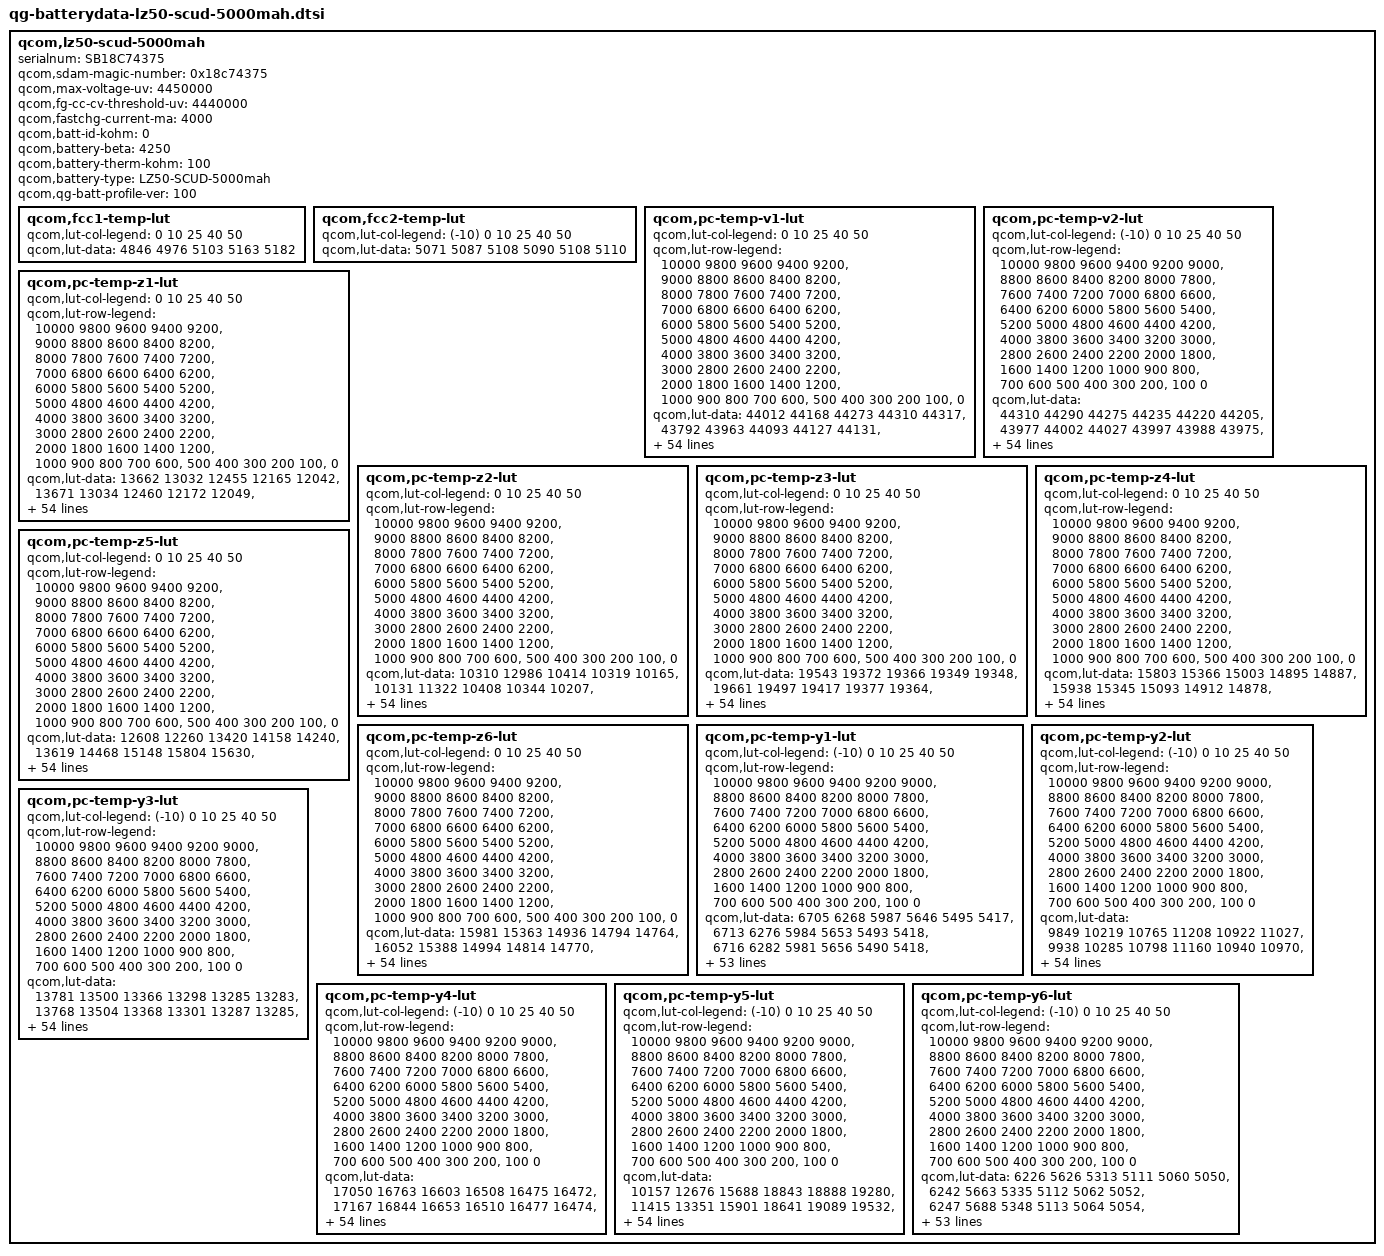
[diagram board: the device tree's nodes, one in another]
qcom,lz50-scud-5000mah {
    /* 4703262_Lenovo_Nairobi_SCUD_5000mAH_PM7250B_averaged_MasterSlave_Jul27th2020 */
    serialnum = "SB18C74375";
    qcom,sdam-magic-number = <0x18c74375>;
    qcom,max-voltage-uv = <4450000>;
    qcom,fg-cc-cv-threshold-uv = <4440000>;
    qcom,fastchg-current-ma = <4000>;
    qcom,batt-id-kohm = <0>;
    qcom,battery-beta = <4250>;
    qcom,battery-therm-kohm = <100>;
    qcom,battery-type = "LZ50-SCUD-5000mah";
    qcom,qg-batt-profile-ver = <100>;

	qcom,fcc1-temp-lut {
		qcom,lut-col-legend = <0 10 25 40 50>;
		qcom,lut-data = <4846 4976 5103 5163 5182>;
	};

	qcom,fcc2-temp-lut {
		qcom,lut-col-legend = <(-10) 0 10 25 40 50>;
		qcom,lut-data = <5071 5087 5108 5090 5108 5110>;
	};

	qcom,pc-temp-v1-lut {
		qcom,lut-col-legend = <0 10 25 40 50>;
		qcom,lut-row-legend = <10000 9800 9600 9400 9200>,
			<9000 8800 8600 8400 8200>,
			<8000 7800 7600 7400 7200>,
			<7000 6800 6600 6400 6200>,
			<6000 5800 5600 5400 5200>,
			<5000 4800 4600 4400 4200>,
			<4000 3800 3600 3400 3200>,
			<3000 2800 2600 2400 2200>,
			<2000 1800 1600 1400 1200>,
			<1000 900 800 700 600>,
			<500 400 300 200 100>,
			<0>;
		qcom,lut-data = <44012 44168 44273 44310 44317>,
			<43792 43963 44093 44127 44131>,
			<43564 43752 43903 43945 43953>,
			<43332 43534 43704 43752 43763>,
			<43096 43309 43491 43549 43562>,
			<42854 43076 43263 43331 43347>,
			<42611 42835 43029 43100 43119>,
			<42371 42590 42786 42863 42884>,
			<42132 42346 42538 42618 42641>,
			<41897 42103 42293 42372 42394>,
			<41666 41865 42051 42127 42148>,
			<41440 41631 41810 41883 41904>,
			<41221 41404 41572 41644 41664>,
			<41009 41183 41338 41407 41428>,
			<40797 40968 41113 41177 41199>,
			<40585 40759 40894 40953 40976>,
			<40378 40551 40684 40736 40759>,
			<40188 40350 40480 40531 40551>,
			<40011 40163 40284 40335 40351>,
			<39843 39987 40103 40145 40159>,
			<39681 39811 39929 39971 39983>,
			<39525 39636 39704 39772 39790>,
			<39373 39454 39378 39478 39515>,
			<39226 39232 39102 39176 39217>,
			<39084 38969 38957 39009 39039>,
			<38944 38775 38851 38903 38928>,
			<38805 38665 38753 38803 38825>,
			<38683 38582 38664 38702 38717>,
			<38572 38512 38581 38605 38613>,
			<38477 38452 38502 38510 38511>,
			<38412 38398 38428 38420 38412>,
			<38362 38346 38361 38337 38322>,
			<38318 38297 38300 38262 38245>,
			<38279 38254 38240 38192 38171>,
			<38243 38216 38184 38124 38098>,
			<38205 38176 38128 38059 38026>,
			<38169 38136 38076 37998 37957>,
			<38126 38092 38027 37944 37891>,
			<38062 38027 37961 37876 37814>,
			<37978 37930 37864 37776 37710>,
			<37875 37817 37748 37655 37588>,
			<37738 37686 37623 37530 37460>,
			<37587 37538 37483 37393 37321>,
			<37418 37369 37319 37235 37165>,
			<37307 37229 37175 37100 37033>,
			<37209 37142 37092 37018 36959>,
			<37174 37113 37065 36994 36933>,
			<37146 37087 37049 36976 36912>,
			<37109 37072 37025 36951 36885>,
			<37031 37000 36943 36856 36777>,
			<36747 36694 36649 36531 36438>,
			<36262 36227 36184 36059 35964>,
			<35638 35618 35576 35447 35357>,
			<34773 34769 34745 34607 34518>,
			<33356 33410 33443 33282 33195>,
			<30000 30000 30000 30000 30000>;
	};

	qcom,pc-temp-v2-lut {
		qcom,lut-col-legend = <(-10) 0 10 25 40 50>;
		qcom,lut-row-legend = <10000 9800 9600 9400 9200 9000>,
			<8800 8600 8400 8200 8000 7800>,
			<7600 7400 7200 7000 6800 6600>,
			<6400 6200 6000 5800 5600 5400>,
			<5200 5000 4800 4600 4400 4200>,
			<4000 3800 3600 3400 3200 3000>,
			<2800 2600 2400 2200 2000 1800>,
			<1600 1400 1200 1000 900 800>,
			<700 600 500 400 300 200>,
			<100 0>;
		qcom,lut-data = <44310 44290 44275 44235 44220 44205>,
			<43977 44002 44027 43997 43988 43975>,
			<43674 43735 43788 43765 43760 43749>,
			<43405 43491 43561 43541 43540 43530>,
			<43169 43272 43347 43325 43328 43319>,
			<42934 43045 43123 43103 43107 43100>,
			<42681 42799 42880 42864 42871 42865>,
			<42431 42545 42630 42619 42628 42624>,
			<42205 42289 42380 42375 42385 42382>,
			<41999 42029 42129 42128 42138 42136>,
			<41765 41783 41883 41885 41894 41893>,
			<41442 41557 41641 41645 41653 41652>,
			<41132 41340 41405 41408 41416 41415>,
			<40965 41132 41172 41177 41183 41182>,
			<40860 40931 40945 40951 40956 40955>,
			<40693 40708 40733 40733 40737 40735>,
			<40297 40446 40544 40522 40526 40522>,
			<39868 40177 40347 40319 40322 40316>,
			<39621 39922 40107 40132 40134 40128>,
			<39437 39674 39841 39953 39950 39946>,
			<39253 39443 39591 39738 39735 39736>,
			<39063 39226 39348 39459 39474 39483>,
			<38876 39027 39132 39196 39229 39243>,
			<38674 38852 38947 38998 39027 39039>,
			<38473 38691 38785 38829 38849 38857>,
			<38337 38518 38639 38684 38702 38709>,
			<38246 38322 38510 38560 38578 38584>,
			<38173 38172 38390 38449 38467 38471>,
			<38106 38090 38278 38343 38363 38364>,
			<38046 38028 38172 38244 38268 38266>,
			<37987 37974 38068 38155 38184 38179>,
			<37926 37926 37967 38074 38108 38100>,
			<37866 37878 37889 37998 38032 38022>,
			<37803 37828 37834 37930 37955 37942>,
			<37740 37777 37789 37865 37873 37858>,
			<37671 37722 37744 37792 37781 37758>,
			<37598 37663 37703 37713 37682 37647>,
			<37520 37597 37653 37632 37584 37542>,
			<37435 37522 37590 37553 37490 37447>,
			<37347 37437 37513 37470 37396 37353>,
			<37261 37336 37412 37378 37305 37261>,
			<37175 37220 37284 37274 37209 37161>,
			<37094 37092 37130 37142 37073 37014>,
			<37016 36961 36982 37005 36947 36889>,
			<36935 36844 36862 36900 36856 36806>,
			<36840 36755 36781 36857 36825 36774>,
			<36789 36717 36742 36841 36812 36760>,
			<36729 36681 36694 36820 36792 36741>,
			<36654 36623 36630 36780 36748 36694>,
			<36541 36515 36507 36658 36584 36509>,
			<36313 36269 36216 36306 36173 36089>,
			<35910 35799 35706 35777 35623 35539>,
			<35268 35125 35011 35088 34896 34809>,
			<34320 34126 34049 34132 33865 33785>,
			<32928 32522 32490 32681 32348 32275>,
			<29705 26763 27162 27333 26870 27058>;
	};

	qcom,pc-temp-z1-lut {
		qcom,lut-col-legend = <0 10 25 40 50>;
		qcom,lut-row-legend = <10000 9800 9600 9400 9200>,
			<9000 8800 8600 8400 8200>,
			<8000 7800 7600 7400 7200>,
			<7000 6800 6600 6400 6200>,
			<6000 5800 5600 5400 5200>,
			<5000 4800 4600 4400 4200>,
			<4000 3800 3600 3400 3200>,
			<3000 2800 2600 2400 2200>,
			<2000 1800 1600 1400 1200>,
			<1000 900 800 700 600>,
			<500 400 300 200 100>,
			<0>;
		qcom,lut-data = <13662 13032 12455 12165 12042>,
			<13671 13034 12460 12172 12049>,
			<13681 13034 12453 12162 12039>,
			<13688 13031 12451 12155 12033>,
			<13691 13027 12449 12149 12029>,
			<13695 13025 12447 12142 12024>,
			<13698 13030 12444 12136 12019>,
			<13686 13034 12434 12130 12016>,
			<13659 13030 12420 12125 12012>,
			<13648 13017 12414 12120 12011>,
			<13660 13002 12411 12116 12011>,
			<13673 12988 12407 12113 12012>,
			<13671 12974 12402 12113 12013>,
			<13651 12970 12399 12114 12015>,
			<13627 12970 12399 12115 12016>,
			<13600 12969 12399 12115 12016>,
			<13575 12965 12399 12114 12016>,
			<13571 12961 12398 12115 12016>,
			<13580 12962 12398 12116 12018>,
			<13586 12967 12400 12116 12019>,
			<13574 12969 12404 12117 12020>,
			<13553 12968 12405 12118 12021>,
			<13540 12967 12405 12118 12021>,
			<13522 12968 12405 12118 12022>,
			<13507 12968 12407 12118 12022>,
			<13512 12969 12411 12121 12025>,
			<13528 12974 12416 12124 12027>,
			<13537 12982 12421 12127 12029>,
			<13539 12986 12425 12132 12031>,
			<13540 12991 12427 12136 12035>,
			<13546 12996 12429 12140 12040>,
			<13563 13002 12433 12144 12046>,
			<13578 13008 12440 12149 12050>,
			<13589 13010 12447 12155 12055>,
			<13598 13010 12455 12161 12061>,
			<13602 13011 12462 12167 12067>,
			<13598 13018 12468 12173 12072>,
			<13595 13028 12474 12178 12076>,
			<13604 13039 12479 12183 12080>,
			<13618 13054 12483 12187 12085>,
			<13625 13064 12487 12192 12089>,
			<13622 13068 12493 12196 12092>,
			<13627 13072 12500 12202 12096>,
			<13673 13081 12509 12207 12099>,
			<13683 13097 12517 12214 12104>,
			<13654 13085 12521 12221 12109>,
			<13651 13110 12519 12220 12108>,
			<13646 13109 12523 12221 12109>,
			<13641 13108 12528 12223 12113>,
			<13675 13103 12534 12231 12119>,
			<13672 13115 12538 12239 12125>,
			<13724 13118 12548 12247 12132>,
			<13685 13157 12558 12259 12145>,
			<13743 13188 12584 12275 12163>,
			<13743 13188 12584 12275 12163>,
			<13743 13188 12584 12275 12163>;
	};

	qcom,pc-temp-z2-lut {
		qcom,lut-col-legend = <0 10 25 40 50>;
		qcom,lut-row-legend = <10000 9800 9600 9400 9200>,
			<9000 8800 8600 8400 8200>,
			<8000 7800 7600 7400 7200>,
			<7000 6800 6600 6400 6200>,
			<6000 5800 5600 5400 5200>,
			<5000 4800 4600 4400 4200>,
			<4000 3800 3600 3400 3200>,
			<3000 2800 2600 2400 2200>,
			<2000 1800 1600 1400 1200>,
			<1000 900 800 700 600>,
			<500 400 300 200 100>,
			<0>;
		qcom,lut-data = <10310 12986 10414 10319 10165>,
			<10131 11322 10408 10344 10207>,
			<10161 10409 10417 10342 10247>,
			<10202 10368 10426 10387 10310>,
			<10209 10340 10423 10414 10356>,
			<10208 10307 10395 10381 10350>,
			<10207 10273 10361 10322 10328>,
			<10204 10241 10327 10290 10305>,
			<10197 10217 10297 10271 10275>,
			<10188 10198 10360 10253 10254>,
			<10171 10182 10578 10228 10242>,
			<10153 10169 10652 10208 10229>,
			<10137 10160 10443 10207 10225>,
			<10122 10160 10238 10210 10219>,
			<10107 10163 10235 10216 10216>,
			<10092 10168 10258 10237 10216>,
			<10080 10178 10276 10257 10216>,
			<10083 10194 10288 10265 10229>,
			<10150 10210 10299 10269 10255>,
			<10210 10229 10310 10270 10268>,
			<10186 10247 10323 10273 10264>,
			<10120 10264 10346 10284 10264>,
			<10097 10281 10405 10357 10314>,
			<10107 10300 10447 10451 10393>,
			<10121 10320 10411 10413 10381>,
			<10134 10329 10346 10228 10238>,
			<10147 10324 10331 10144 10159>,
			<10159 10317 10337 10162 10174>,
			<10169 10312 10346 10195 10209>,
			<10178 10306 10360 10257 10302>,
			<10184 10303 10375 10353 10482>,
			<10189 10305 10380 10395 10539>,
			<10194 10310 10382 10412 10457>,
			<10201 10316 10384 10417 10357>,
			<10210 10325 10393 10390 10291>,
			<10219 10333 10403 10346 10239>,
			<10231 10339 10409 10340 10237>,
			<10244 10346 10418 10357 10286>,
			<10256 10357 10432 10380 10337>,
			<10269 10374 10461 10431 10373>,
			<10282 10388 10484 10483 10406>,
			<10297 10395 10486 10495 10436>,
			<10319 10403 10486 10500 10465>,
			<10364 10417 10485 10496 10479>,
			<10124 10527 10504 10449 10456>,
			<10244 10593 10527 10328 10293>,
			<9989 10605 10521 10325 10276>,
			<9808 10599 10503 10330 10276>,
			<9870 10722 10523 10369 10328>,
			<9820 10782 10582 10409 10352>,
			<9739 10712 10581 10388 10238>,
			<9621 10614 10531 10254 10080>,
			<9547 10491 10467 10149 10017>,
			<9600 10287 10384 10074 9961>,
			<9600 10287 10384 10074 9961>,
			<9600 10287 10384 10074 9961>;
	};

	qcom,pc-temp-z3-lut {
		qcom,lut-col-legend = <0 10 25 40 50>;
		qcom,lut-row-legend = <10000 9800 9600 9400 9200>,
			<9000 8800 8600 8400 8200>,
			<8000 7800 7600 7400 7200>,
			<7000 6800 6600 6400 6200>,
			<6000 5800 5600 5400 5200>,
			<5000 4800 4600 4400 4200>,
			<4000 3800 3600 3400 3200>,
			<3000 2800 2600 2400 2200>,
			<2000 1800 1600 1400 1200>,
			<1000 900 800 700 600>,
			<500 400 300 200 100>,
			<0>;
		qcom,lut-data = <19543 19372 19366 19349 19348>,
			<19661 19497 19417 19377 19364>,
			<19724 19576 19442 19400 19383>,
			<19766 19599 19459 19416 19400>,
			<19776 19610 19471 19427 19412>,
			<19778 19614 19480 19436 19423>,
			<19779 19617 19485 19443 19432>,
			<19773 19620 19487 19447 19438>,
			<19763 19621 19489 19449 19442>,
			<19759 19621 19494 19450 19445>,
			<19758 19621 19507 19449 19446>,
			<19757 19619 19510 19447 19446>,
			<19758 19615 19495 19443 19443>,
			<19761 19611 19477 19437 19435>,
			<19765 19605 19470 19432 19427>,
			<19770 19598 19465 19428 19421>,
			<19775 19591 19460 19425 19415>,
			<19778 19583 19456 19419 19410>,
			<19792 19577 19453 19413 19405>,
			<19805 19571 19449 19407 19399>,
			<19797 19569 19446 19401 19391>,
			<19778 19571 19447 19398 19387>,
			<19770 19576 19464 19404 19389>,
			<19771 19585 19478 19413 19393>,
			<19772 19602 19471 19409 19389>,
			<19772 19610 19456 19388 19367>,
			<19775 19607 19448 19376 19355>,
			<19776 19601 19443 19374 19359>,
			<19774 19596 19441 19373 19369>,
			<19772 19590 19443 19378 19387>,
			<19767 19585 19446 19395 19418>,
			<19755 19581 19449 19407 19428>,
			<19743 19579 19452 19417 19424>,
			<19733 19575 19455 19422 19417>,
			<19724 19572 19457 19420 19408>,
			<19714 19569 19458 19414 19396>,
			<19705 19564 19456 19406 19387>,
			<19695 19559 19449 19396 19381>,
			<19685 19555 19444 19391 19376>,
			<19676 19550 19442 19390 19372>,
			<19667 19545 19440 19390 19370>,
			<19658 19540 19437 19390 19372>,
			<19647 19534 19433 19391 19382>,
			<19629 19526 19429 19391 19386>,
			<19389 19494 19420 19386 19384>,
			<19333 19465 19401 19369 19360>,
			<19298 19457 19401 19363 19355>,
			<19270 19455 19394 19360 19350>,
			<19267 19334 19390 19350 19338>,
			<19268 19327 19386 19348 19344>,
			<19269 19435 19380 19378 19376>,
			<19277 19392 19394 19389 19383>,
			<19284 19327 19399 19388 19379>,
			<19323 19321 19397 19387 19379>,
			<19323 19321 19397 19387 19379>,
			<19323 19321 19397 19387 19379>;
	};

	qcom,pc-temp-z4-lut {
		qcom,lut-col-legend = <0 10 25 40 50>;
		qcom,lut-row-legend = <10000 9800 9600 9400 9200>,
			<9000 8800 8600 8400 8200>,
			<8000 7800 7600 7400 7200>,
			<7000 6800 6600 6400 6200>,
			<6000 5800 5600 5400 5200>,
			<5000 4800 4600 4400 4200>,
			<4000 3800 3600 3400 3200>,
			<3000 2800 2600 2400 2200>,
			<2000 1800 1600 1400 1200>,
			<1000 900 800 700 600>,
			<500 400 300 200 100>,
			<0>;
		qcom,lut-data = <15803 15366 15003 14895 14887>,
			<15938 15345 15093 14912 14878>,
			<15869 15314 15078 14952 14913>,
			<15716 15258 15032 14928 14898>,
			<15587 15166 14989 14898 14874>,
			<15478 15086 14945 14874 14854>,
			<15384 15024 14906 14850 14833>,
			<15311 14971 14875 14828 14813>,
			<15250 14928 14846 14807 14795>,
			<15194 14891 14808 14789 14778>,
			<15141 14861 14762 14772 14761>,
			<15093 14836 14741 14757 14746>,
			<15053 14815 14742 14744 14735>,
			<15016 14798 14745 14732 14727>,
			<14982 14783 14738 14723 14721>,
			<14952 14772 14728 14717 14718>,
			<14925 14764 14722 14712 14715>,
			<14897 14758 14718 14708 14711>,
			<14853 14751 14715 14705 14707>,
			<14819 14745 14712 14704 14706>,
			<14814 14742 14710 14704 14706>,
			<14820 14740 14718 14706 14708>,
			<14818 14739 14791 14762 14754>,
			<14806 14755 14851 14842 14836>,
			<14797 14812 14857 14858 14857>,
			<14797 14843 14859 14862 14862>,
			<14801 14841 14858 14863 14863>,
			<14806 14835 14845 14853 14849>,
			<14813 14827 14829 14835 14822>,
			<14820 14814 14813 14813 14787>,
			<14820 14802 14796 14784 14741>,
			<14815 14790 14779 14759 14717>,
			<14808 14779 14762 14733 14707>,
			<14801 14769 14749 14717 14702>,
			<14793 14759 14738 14715 14703>,
			<14785 14751 14732 14713 14706>,
			<14776 14743 14729 14713 14706>,
			<14767 14738 14728 14711 14705>,
			<14758 14737 14728 14711 14705>,
			<14750 14737 14733 14719 14716>,
			<14744 14736 14738 14729 14731>,
			<14741 14732 14736 14728 14729>,
			<14735 14724 14728 14721 14718>,
			<14723 14716 14722 14718 14714>,
			<14880 14691 14705 14709 14704>,
			<14912 14676 14675 14683 14682>,
			<14943 14671 14666 14677 14678>,
			<14965 14668 14656 14663 14663>,
			<14962 14794 14648 14650 14648>,
			<14950 14793 14651 14650 14640>,
			<14946 14683 14683 14664 14664>,
			<14970 14742 14677 14667 14674>,
			<14973 14824 14674 14674 14684>,
			<14954 14840 14679 14681 14690>,
			<14954 14840 14679 14681 14690>,
			<14954 14840 14679 14681 14690>;
	};

	qcom,pc-temp-z5-lut {
		qcom,lut-col-legend = <0 10 25 40 50>;
		qcom,lut-row-legend = <10000 9800 9600 9400 9200>,
			<9000 8800 8600 8400 8200>,
			<8000 7800 7600 7400 7200>,
			<7000 6800 6600 6400 6200>,
			<6000 5800 5600 5400 5200>,
			<5000 4800 4600 4400 4200>,
			<4000 3800 3600 3400 3200>,
			<3000 2800 2600 2400 2200>,
			<2000 1800 1600 1400 1200>,
			<1000 900 800 700 600>,
			<500 400 300 200 100>,
			<0>;
		qcom,lut-data = <12608 12260 13420 14158 14240>,
			<13619 14468 15148 15804 15630>,
			<14196 15951 15947 16604 16446>,
			<14610 16480 16595 17418 17469>,
			<14876 16752 17105 18103 18391>,
			<15068 16986 17517 18643 19240>,
			<15199 17302 17895 19116 20037>,
			<15309 17728 18285 19605 20836>,
			<15427 18267 18763 20097 21743>,
			<15570 18937 20144 20594 22643>,
			<15823 19611 23046 21078 23881>,
			<16108 20322 24278 21606 25145>,
			<16381 21052 23221 22293 25626>,
			<16777 21693 22217 23164 26013>,
			<17292 22266 22681 24078 26179>,
			<17989 22877 23541 25130 26205>,
			<18822 23642 24342 25947 26319>,
			<19903 24441 25059 26301 26850>,
			<22300 25028 25762 26489 27734>,
			<24304 25457 26359 26499 27966>,
			<24451 26217 26968 26253 27457>,
			<24126 29014 29318 26402 26987>,
			<24759 33710 40962 28855 27124>,
			<27339 40325 49744 31918 27454>,
			<30777 49990 43852 30384 26190>,
			<34465 54328 32135 22910 20071>,
			<38781 50025 26855 18562 16685>,
			<41524 43228 24252 17413 16675>,
			<43085 39132 23231 16851 16672>,
			<44061 35973 23337 17330 18334>,
			<43510 34642 23622 19020 23679>,
			<40827 34591 24261 21196 27086>,
			<38415 34720 25977 24859 28880>,
			<37125 35109 28161 27950 29788>,
			<36137 36102 31808 29599 29322>,
			<35452 37020 34973 30918 28335>,
			<34839 37730 35117 30829 27949>,
			<34511 38326 34568 29308 27845>,
			<34798 38631 34239 28196 27653>,
			<35471 38925 33786 27930 26244>,
			<35734 39063 33092 27708 24544>,
			<35811 38268 31620 26939 24620>,
			<35872 37146 29752 25742 25734>,
			<35325 36519 29510 25991 27526>,
			<17806 35805 30479 25818 28170>,
			<12446 31331 29912 23760 22376>,
			<11898 28747 30834 22306 20675>,
			<11463 28039 28978 23603 21760>,
			<11446 13009 29463 23720 22259>,
			<11494 13060 27695 22300 28180>,
			<11564 23635 20738 26278 28028>,
			<11504 16911 21546 24849 24492>,
			<11472 12555 21439 21982 20197>,
			<11841 12200 19909 19332 17746>,
			<11841 12200 19909 19332 17746>,
			<11841 12200 19909 19332 17746>;
	};

	qcom,pc-temp-z6-lut {
		qcom,lut-col-legend = <0 10 25 40 50>;
		qcom,lut-row-legend = <10000 9800 9600 9400 9200>,
			<9000 8800 8600 8400 8200>,
			<8000 7800 7600 7400 7200>,
			<7000 6800 6600 6400 6200>,
			<6000 5800 5600 5400 5200>,
			<5000 4800 4600 4400 4200>,
			<4000 3800 3600 3400 3200>,
			<3000 2800 2600 2400 2200>,
			<2000 1800 1600 1400 1200>,
			<1000 900 800 700 600>,
			<500 400 300 200 100>,
			<0>;
		qcom,lut-data = <15981 15363 14936 14794 14764>,
			<16052 15388 14994 14814 14770>,
			<16020 15394 14992 14840 14792>,
			<15943 15372 14979 14836 14793>,
			<15872 15321 14964 14831 14792>,
			<15802 15274 14946 14824 14789>,
			<15739 15235 14928 14816 14784>,
			<15687 15202 14912 14808 14779>,
			<15643 15174 14897 14800 14773>,
			<15604 15149 14883 14792 14768>,
			<15569 15128 14869 14784 14762>,
			<15539 15110 14857 14776 14756>,
			<15515 15094 14848 14768 14749>,
			<15496 15080 14839 14760 14742>,
			<15477 15066 14831 14753 14735>,
			<15456 15055 14824 14748 14730>,
			<15435 15044 14819 14744 14725>,
			<15419 15035 14814 14739 14720>,
			<15407 15028 14811 14734 14716>,
			<15395 15023 14808 14730 14712>,
			<15383 15021 14806 14727 14708>,
			<15373 15022 14810 14725 14706>,
			<15365 15025 14851 14754 14727>,
			<15359 15038 14884 14793 14765>,
			<15355 15073 14882 14797 14771>,
			<15354 15091 14878 14789 14764>,
			<15358 15089 14873 14782 14756>,
			<15362 15085 14866 14776 14751>,
			<15366 15081 14860 14770 14747>,
			<15370 15074 14855 14766 14743>,
			<15369 15067 14851 14763 14740>,
			<15362 15062 14846 14759 14737>,
			<15354 15057 14842 14754 14731>,
			<15349 15053 14839 14751 14726>,
			<15343 15049 14837 14748 14722>,
			<15337 15046 14836 14746 14717>,
			<15331 15043 14834 14742 14714>,
			<15327 15041 14831 14737 14709>,
			<15324 15041 14830 14735 14707>,
			<15322 15043 14833 14738 14710>,
			<15321 15044 14836 14742 14715>,
			<15324 15043 14835 14742 14716>,
			<15324 15042 14832 14741 14716>,
			<15322 15041 14830 14741 14717>,
			<15289 15026 14821 14735 14713>,
			<15275 15010 14803 14715 14691>,
			<15271 15004 14799 14710 14686>,
			<15269 15003 14791 14702 14677>,
			<15269 14997 14787 14692 14664>,
			<15272 14998 14788 14692 14665>,
			<15280 15013 14802 14715 14693>,
			<15302 15024 14811 14725 14705>,
			<15320 15036 14817 14731 14710>,
			<15352 15056 14825 14738 14717>,
			<15352 15056 14825 14738 14717>,
			<15352 15056 14825 14738 14717>;
	};

	qcom,pc-temp-y1-lut {
		qcom,lut-col-legend = <(-10) 0 10 25 40 50>;
		qcom,lut-row-legend = <10000 9800 9600 9400 9200 9000>,
			<8800 8600 8400 8200 8000 7800>,
			<7600 7400 7200 7000 6800 6600>,
			<6400 6200 6000 5800 5600 5400>,
			<5200 5000 4800 4600 4400 4200>,
			<4000 3800 3600 3400 3200 3000>,
			<2800 2600 2400 2200 2000 1800>,
			<1600 1400 1200 1000 900 800>,
			<700 600 500 400 300 200>,
			<100 0>;
		qcom,lut-data = <6705 6268 5987 5646 5495 5417>,
			<6713 6276 5984 5653 5493 5418>,
			<6716 6282 5981 5656 5490 5418>,
			<6716 6286 5977 5657 5488 5417>,
			<6715 6290 5975 5657 5486 5416>,
			<6714 6293 5973 5656 5484 5415>,
			<6709 6295 5973 5652 5482 5413>,
			<6702 6296 5973 5647 5480 5411>,
			<6702 6296 5972 5645 5477 5409>,
			<6706 6293 5971 5644 5475 5407>,
			<6707 6290 5970 5643 5472 5405>,
			<6703 6287 5971 5640 5470 5403>,
			<6696 6285 5971 5638 5467 5402>,
			<6698 6288 5971 5637 5466 5401>,
			<6706 6297 5970 5636 5465 5400>,
			<6710 6300 5970 5636 5465 5400>,
			<6718 6294 5971 5636 5464 5400>,
			<6727 6288 5972 5635 5464 5400>,
			<6724 6291 5970 5636 5464 5400>,
			<6714 6298 5968 5638 5464 5399>,
			<6709 6299 5967 5638 5465 5399>,
			<6709 6299 5968 5640 5466 5400>,
			<6711 6300 5969 5641 5466 5401>,
			<6714 6301 5970 5644 5468 5402>,
			<6719 6304 5971 5647 5471 5404>,
			<6718 6305 5973 5651 5473 5406>,
			<6709 6306 5980 5654 5475 5408>,
			<6700 6306 5986 5657 5478 5410>,
			<6696 6306 5989 5661 5480 5413>,
			<6693 6306 5992 5664 5483 5416>,
			<6692 6307 5989 5666 5487 5419>,
			<6691 6311 5982 5667 5492 5423>,
			<6690 6313 5979 5669 5496 5426>,
			<6690 6307 5983 5671 5500 5428>,
			<6690 6298 5988 5674 5502 5430>,
			<6688 6293 5985 5678 5505 5433>,
			<6680 6289 5978 5685 5507 5435>,
			<6675 6286 5975 5688 5508 5436>,
			<6679 6286 5979 5689 5509 5438>,
			<6684 6285 5982 5689 5510 5439>,
			<6690 6285 5983 5689 5511 5441>,
			<6710 6286 5986 5688 5511 5442>,
			<6712 6283 5983 5692 5516 5445>,
			<6710 6281 5990 5698 5521 5450>,
			<6715 6321 6004 5702 5525 5454>,
			<6742 6335 6000 5704 5528 5453>,
			<6756 6321 6001 5705 5525 5452>,
			<6751 6318 6003 5706 5524 5453>,
			<6727 6330 6004 5706 5524 5453>,
			<6761 6352 6003 5703 5525 5454>,
			<6775 6355 6014 5705 5529 5459>,
			<6853 6355 6028 5720 5539 5465>,
			<6970 6384 6041 5734 5549 5473>,
			<7034 6484 6084 5753 5559 5485>,
			<7034 6484 6084 5753 5559 5485>,
			<7034 6484 6084 5753 5559 5485>;
	};

	qcom,pc-temp-y2-lut {
		qcom,lut-col-legend = <(-10) 0 10 25 40 50>;
		qcom,lut-row-legend = <10000 9800 9600 9400 9200 9000>,
			<8800 8600 8400 8200 8000 7800>,
			<7600 7400 7200 7000 6800 6600>,
			<6400 6200 6000 5800 5600 5400>,
			<5200 5000 4800 4600 4400 4200>,
			<4000 3800 3600 3400 3200 3000>,
			<2800 2600 2400 2200 2000 1800>,
			<1600 1400 1200 1000 900 800>,
			<700 600 500 400 300 200>,
			<100 0>;
		qcom,lut-data = <9849 10219 10765 11208 10922 11027>,
			<9938 10285 10798 11160 10940 10970>,
			<10026 10366 10827 11114 10943 10902>,
			<10107 10447 10849 11072 10936 10835>,
			<10177 10513 10863 11034 10921 10780>,
			<10231 10550 10867 11003 10902 10748>,
			<10265 10567 10859 10977 10867 10733>,
			<10297 10578 10847 10956 10833 10723>,
			<10370 10581 10845 10941 10824 10717>,
			<10502 10582 10845 10931 10820 10716>,
			<10551 10589 10845 10922 10818 10715>,
			<10180 10717 10863 10914 10814 10691>,
			<9744 10856 10892 10909 10812 10665>,
			<9795 10852 10921 10915 10815 10669>,
			<10069 10808 10957 10937 10826 10684>,
			<10168 10798 11002 10967 10839 10694>,
			<9933 10893 11068 11023 10855 10707>,
			<9696 10988 11120 11089 10881 10726>,
			<9681 10997 11139 11161 10952 10782>,
			<9679 10995 11152 11234 11062 10884>,
			<9678 11000 11153 11250 11112 10975>,
			<9676 11021 11152 11229 11136 11077>,
			<9674 11037 11154 11212 11149 11128>,
			<9672 10969 11166 11217 11150 11095>,
			<9671 10785 11183 11230 11148 11040>,
			<9670 10540 11201 11244 11160 11048>,
			<9669 10070 11226 11267 11206 11140>,
			<9668 9767 11237 11290 11243 11208>,
			<9667 9727 11204 11314 11253 11212>,
			<9667 9706 11159 11340 11261 11205>,
			<9666 9694 11151 11365 11302 11244>,
			<9666 9686 11149 11390 11396 11346>,
			<9666 9681 11145 11402 11437 11395>,
			<9665 9677 11126 11401 11432 11426>,
			<9664 9674 11097 11394 11418 11453>,
			<9664 9671 11069 11382 11377 11403>,
			<9664 9669 11038 11354 11295 11270>,
			<9664 9667 10998 11324 11230 11219>,
			<9664 9665 10948 11286 11165 11214>,
			<9663 9664 10874 11254 11123 11210>,
			<9663 9664 10637 11243 11160 11207>,
			<9663 9663 10264 11237 11215 11201>,
			<9663 9662 9857 11211 11195 11079>,
			<9663 9662 9714 11168 11095 10907>,
			<9662 9662 9726 11141 10970 10828>,
			<9662 9661 9696 11112 10960 10831>,
			<9661 9661 9688 11117 10986 10870>,
			<9661 9660 9680 11110 11027 10908>,
			<9660 9660 9676 11128 11049 10927>,
			<9659 9659 9673 11140 11033 10865>,
			<9656 9658 9669 11090 10948 10739>,
			<9653 9657 9664 10992 10847 10667>,
			<9651 9654 9660 10889 10756 10596>,
			<9650 9651 9657 10813 10627 10482>,
			<9650 9651 9657 10813 10627 10482>,
			<9650 9651 9657 10813 10627 10482>;
	};

	qcom,pc-temp-y3-lut {
		qcom,lut-col-legend = <(-10) 0 10 25 40 50>;
		qcom,lut-row-legend = <10000 9800 9600 9400 9200 9000>,
			<8800 8600 8400 8200 8000 7800>,
			<7600 7400 7200 7000 6800 6600>,
			<6400 6200 6000 5800 5600 5400>,
			<5200 5000 4800 4600 4400 4200>,
			<4000 3800 3600 3400 3200 3000>,
			<2800 2600 2400 2200 2000 1800>,
			<1600 1400 1200 1000 900 800>,
			<700 600 500 400 300 200>,
			<100 0>;
		qcom,lut-data = <13781 13500 13366 13298 13285 13283>,
			<13768 13504 13368 13301 13287 13285>,
			<13754 13507 13370 13303 13289 13286>,
			<13739 13508 13374 13305 13291 13288>,
			<13724 13508 13376 13306 13292 13289>,
			<13708 13507 13377 13307 13294 13290>,
			<13690 13505 13377 13308 13294 13291>,
			<13674 13502 13377 13309 13295 13291>,
			<13663 13496 13377 13310 13296 13292>,
			<13657 13486 13377 13311 13296 13293>,
			<13646 13481 13376 13312 13297 13294>,
			<13608 13488 13375 13312 13298 13294>,
			<13568 13496 13373 13313 13298 13295>,
			<13561 13482 13369 13313 13299 13295>,
			<13565 13441 13364 13313 13300 13296>,
			<13566 13425 13362 13313 13301 13297>,
			<13548 13429 13363 13313 13303 13297>,
			<13529 13433 13364 13313 13304 13297>,
			<13529 13426 13361 13313 13304 13298>,
			<13531 13408 13355 13313 13302 13300>,
			<13534 13394 13349 13312 13300 13300>,
			<13543 13384 13343 13308 13296 13295>,
			<13550 13375 13337 13304 13293 13290>,
			<13545 13370 13334 13301 13290 13288>,
			<13533 13365 13331 13299 13289 13286>,
			<13531 13360 13329 13298 13288 13286>,
			<13549 13354 13328 13298 13287 13286>,
			<13575 13351 13326 13297 13287 13287>,
			<13602 13355 13325 13297 13286 13285>,
			<13633 13363 13323 13296 13285 13283>,
			<13665 13375 13322 13296 13285 13283>,
			<13696 13396 13321 13295 13286 13283>,
			<13731 13420 13320 13295 13287 13283>,
			<13773 13446 13321 13295 13286 13284>,
			<13818 13477 13322 13296 13286 13285>,
			<13860 13513 13325 13296 13286 13285>,
			<13898 13557 13329 13296 13286 13284>,
			<13936 13606 13332 13296 13286 13284>,
			<13974 13664 13335 13297 13286 13285>,
			<14011 13725 13338 13297 13286 13287>,
			<14043 13783 13345 13298 13287 13287>,
			<14071 13839 13355 13299 13289 13288>,
			<14104 13896 13367 13299 13288 13285>,
			<14143 13950 13375 13299 13286 13284>,
			<14164 13955 13372 13299 13287 13287>,
			<14198 14020 13401 13302 13296 13294>,
			<14261 14083 13422 13306 13298 13296>,
			<14340 14156 13456 13311 13301 13298>,
			<14462 14225 13505 13315 13302 13299>,
			<14656 14317 13558 13315 13298 13294>,
			<15092 14452 13616 13310 13295 13292>,
			<16669 14729 13761 13313 13297 13294>,
			<21755 15764 14110 13320 13303 13300>,
			<38318 19894 14689 13333 13313 13314>,
			<38318 19894 14689 13333 13313 13314>,
			<38318 19894 14689 13333 13313 13314>;
	};

	qcom,pc-temp-y4-lut {
		qcom,lut-col-legend = <(-10) 0 10 25 40 50>;
		qcom,lut-row-legend = <10000 9800 9600 9400 9200 9000>,
			<8800 8600 8400 8200 8000 7800>,
			<7600 7400 7200 7000 6800 6600>,
			<6400 6200 6000 5800 5600 5400>,
			<5200 5000 4800 4600 4400 4200>,
			<4000 3800 3600 3400 3200 3000>,
			<2800 2600 2400 2200 2000 1800>,
			<1600 1400 1200 1000 900 800>,
			<700 600 500 400 300 200>,
			<100 0>;
		qcom,lut-data = <17050 16763 16603 16508 16475 16472>,
			<17167 16844 16653 16510 16477 16474>,
			<17272 16944 16706 16514 16478 16476>,
			<17357 17041 16753 16517 16479 16479>,
			<17413 17113 16786 16520 16480 16481>,
			<17432 17139 16797 16521 16481 16482>,
			<17410 17125 16788 16520 16482 16482>,
			<17371 17105 16773 16520 16483 16482>,
			<17338 17094 16762 16520 16484 16483>,
			<17304 17088 16752 16521 16487 16484>,
			<17292 17078 16748 16524 16489 16485>,
			<17355 17054 16751 16528 16493 16488>,
			<17429 17032 16755 16535 16497 16491>,
			<17432 17064 16766 16543 16502 16495>,
			<17418 17157 16786 16553 16508 16499>,
			<17389 17188 16807 16565 16515 16504>,
			<17253 17105 16832 16583 16522 16511>,
			<17099 17001 16848 16604 16532 16519>,
			<17039 16946 16824 16633 16556 16536>,
			<17003 16903 16766 16666 16589 16557>,
			<16959 16863 16715 16668 16592 16559>,
			<16896 16825 16668 16602 16561 16543>,
			<16835 16790 16634 16539 16527 16524>,
			<16781 16757 16614 16515 16502 16502>,
			<16734 16727 16600 16500 16482 16482>,
			<16723 16691 16591 16498 16480 16479>,
			<16724 16643 16586 16500 16483 16480>,
			<16725 16617 16580 16503 16488 16482>,
			<16725 16624 16570 16508 16496 16489>,
			<16725 16637 16558 16513 16507 16501>,
			<16726 16644 16541 16519 16517 16512>,
			<16730 16649 16517 16526 16529 16523>,
			<16733 16655 16509 16531 16534 16530>,
			<16736 16664 16518 16533 16534 16532>,
			<16738 16675 16534 16534 16534 16534>,
			<16739 16686 16551 16530 16527 16527>,
			<16739 16700 16574 16515 16506 16509>,
			<16739 16706 16594 16507 16495 16500>,
			<16736 16707 16614 16505 16491 16498>,
			<16732 16707 16629 16505 16489 16497>,
			<16731 16705 16638 16509 16495 16503>,
			<16734 16698 16644 16519 16504 16513>,
			<16740 16687 16647 16515 16485 16486>,
			<16749 16676 16649 16508 16471 16466>,
			<16753 16659 16623 16495 16467 16463>,
			<16744 16666 16637 16509 16499 16512>,
			<16758 16682 16660 16528 16531 16550>,
			<16778 16707 16695 16556 16567 16586>,
			<16802 16740 16741 16595 16596 16609>,
			<16813 16771 16788 16601 16568 16568>,
			<16819 16770 16800 16544 16496 16502>,
			<16961 16740 16798 16540 16496 16502>,
			<17904 16833 16846 16562 16502 16501>,
			<27350 18186 16938 16606 16525 16516>,
			<27350 18186 16938 16606 16525 16516>,
			<27350 18186 16938 16606 16525 16516>;
	};

	qcom,pc-temp-y5-lut {
		qcom,lut-col-legend = <(-10) 0 10 25 40 50>;
		qcom,lut-row-legend = <10000 9800 9600 9400 9200 9000>,
			<8800 8600 8400 8200 8000 7800>,
			<7600 7400 7200 7000 6800 6600>,
			<6400 6200 6000 5800 5600 5400>,
			<5200 5000 4800 4600 4400 4200>,
			<4000 3800 3600 3400 3200 3000>,
			<2800 2600 2400 2200 2000 1800>,
			<1600 1400 1200 1000 900 800>,
			<700 600 500 400 300 200>,
			<100 0>;
		qcom,lut-data = <10157 12676 15688 18843 18888 19280>,
			<11415 13351 15901 18641 19089 19532>,
			<12648 14009 16123 18427 19158 19592>,
			<13790 14619 16336 18202 19127 19502>,
			<14777 15150 16522 17968 19024 19306>,
			<15541 15569 16663 17724 18874 19044>,
			<16040 15953 16792 17462 18494 18622>,
			<16496 16218 16882 17197 17973 18142>,
			<17349 16169 16863 16959 17545 17804>,
			<18699 15904 16753 16731 17145 17527>,
			<19227 15817 16607 16450 16739 17234>,
			<16760 16854 16365 16031 16299 16847>,
			<13868 17991 16053 15578 15890 16440>,
			<14985 17729 15671 15180 15537 16087>,
			<19293 16786 15245 14797 15218 15733>,
			<20961 16574 15271 14599 15091 15358>,
			<17938 18496 17032 14414 15062 14881>,
			<14811 20290 19019 14297 15028 14538>,
			<14965 20162 20147 14826 14857 14465>,
			<16048 19738 21064 16312 14606 14506>,
			<17062 19654 21279 17978 14993 14978>,
			<18106 20049 21154 20449 17925 17209>,
			<18769 20650 21062 21994 19952 18897>,
			<17407 21651 21186 21639 19935 19267>,
			<14255 22878 21416 20938 19842 19474>,
			<13048 22428 21672 20641 19551 19415>,
			<12798 17489 22308 20502 18593 18937>,
			<12695 13713 23087 20367 17696 18265>,
			<12792 13190 24220 20169 17014 16921>,
			<13017 12913 25206 19988 16542 15639>,
			<13190 12962 24839 20036 16721 15560>,
			<13316 13388 22968 20483 17590 15793>,
			<13454 13808 21427 21131 18457 16175>,
			<13689 14080 20311 22533 19150 17329>,
			<13955 14309 19606 23984 19887 18809>,
			<14076 14499 19683 24097 20968 19956>,
			<14179 14671 19990 23593 22233 21003>,
			<14222 14850 20105 23074 22482 21800>,
			<14150 15126 20072 22359 21114 22488>,
			<14006 15343 20015 21502 19924 22860>,
			<13799 15279 19469 20690 20190 22511>,
			<13485 15055 18192 19963 20772 22042>,
			<13415 14847 16204 19375 20990 21305>,
			<13473 14535 14748 18951 19789 19869>,
			<13529 14152 14519 19481 17444 17989>,
			<13584 14099 14715 18788 18061 16822>,
			<13842 14104 14451 18634 17625 16111>,
			<13950 14437 14515 18563 17348 16009>,
			<14208 14458 15447 18754 17268 15988>,
			<14606 14877 16333 19028 17087 15577>,
			<14176 14944 16169 19449 17970 16223>,
			<12340 14245 15170 19692 17585 15687>,
			<10163 12921 14005 19767 18072 16163>,
			<9123 10234 13180 21295 22507 22863>,
			<9123 10234 13180 21295 22507 22863>,
			<9123 10234 13180 21295 22507 22863>;
	};

	qcom,pc-temp-y6-lut {
		qcom,lut-col-legend = <(-10) 0 10 25 40 50>;
		qcom,lut-row-legend = <10000 9800 9600 9400 9200 9000>,
			<8800 8600 8400 8200 8000 7800>,
			<7600 7400 7200 7000 6800 6600>,
			<6400 6200 6000 5800 5600 5400>,
			<5200 5000 4800 4600 4400 4200>,
			<4000 3800 3600 3400 3200 3000>,
			<2800 2600 2400 2200 2000 1800>,
			<1600 1400 1200 1000 900 800>,
			<700 600 500 400 300 200>,
			<100 0>;
		qcom,lut-data = <6226 5626 5313 5111 5060 5050>,
			<6242 5663 5335 5112 5062 5052>,
			<6247 5688 5348 5113 5064 5054>,
			<6244 5702 5354 5115 5066 5056>,
			<6236 5709 5357 5116 5067 5057>,
			<6224 5710 5357 5116 5068 5058>,
			<6201 5702 5351 5116 5069 5059>,
			<6172 5688 5341 5115 5069 5059>,
			<6153 5675 5333 5115 5070 5060>,
			<6138 5661 5326 5116 5071 5061>,
			<6119 5652 5321 5116 5072 5062>,
			<6077 5646 5317 5117 5073 5063>,
			<6040 5643 5315 5119 5075 5064>,
			<6041 5642 5315 5121 5076 5065>,
			<6056 5641 5315 5123 5078 5067>,
			<6059 5638 5316 5127 5081 5069>,
			<5996 5621 5322 5131 5084 5071>,
			<5926 5597 5327 5137 5088 5073>,
			<5912 5578 5319 5145 5095 5079>,
			<5907 5559 5298 5154 5102 5086>,
			<5900 5544 5280 5154 5102 5086>,
			<5893 5531 5262 5133 5090 5078>,
			<5884 5521 5250 5112 5077 5068>,
			<5872 5516 5243 5104 5068 5060>,
			<5859 5511 5239 5098 5061 5053>,
			<5857 5504 5238 5097 5061 5052>,
			<5874 5491 5238 5098 5061 5053>,
			<5898 5483 5238 5100 5062 5054>,
			<5921 5495 5237 5101 5064 5055>,
			<5946 5521 5236 5103 5067 5057>,
			<5972 5548 5235 5105 5071 5060>,
			<6000 5578 5234 5108 5075 5063>,
			<6030 5611 5233 5111 5077 5066>,
			<6060 5646 5242 5113 5078 5068>,
			<6091 5684 5256 5115 5078 5069>,
			<6122 5725 5273 5114 5076 5067>,
			<6154 5769 5293 5111 5070 5061>,
			<6184 5815 5316 5110 5067 5059>,
			<6212 5866 5341 5111 5066 5060>,
			<6237 5916 5367 5112 5066 5061>,
			<6262 5962 5392 5116 5069 5063>,
			<6286 6006 5417 5121 5073 5067>,
			<6316 6049 5441 5121 5067 5057>,
			<6353 6090 5469 5122 5063 5052>,
			<6376 6096 5459 5120 5063 5053>,
			<6412 6151 5506 5129 5079 5073>,
			<6465 6203 5546 5138 5090 5085>,
			<6536 6266 5600 5149 5102 5097>,
			<6640 6332 5661 5162 5110 5104>,
			<6802 6416 5722 5164 5100 5089>,
			<7154 6522 5787 5146 5078 5069>,
			<8416 6733 5918 5152 5080 5071>,
			<12339 7558 6217 5171 5088 5077>,
			<26477 10891 6695 5204 5104 5094>,
			<26477 10891 6695 5204 5104 5094>,
			<26477 10891 6695 5204 5104 5094>;
	};

};
